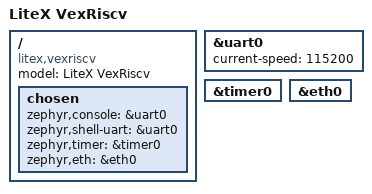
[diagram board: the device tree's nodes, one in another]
/dts-v1/;

#include <riscv32-litex-vexriscv.dtsi>

/ {
	model = "LiteX VexRiscv";
	compatible = "litex,vexriscv";
	chosen {
		zephyr,console = &uart0;
        zephyr,shell-uart = &uart0;
        zephyr,timer = &timer0;
        zephyr,eth = &eth0;
	};
};

&uart0 {
	status = "ok";
	current-speed = <115200>;
};

&timer0 {
    status = "ok";
};

&eth0 {
    status = "ok";
};
